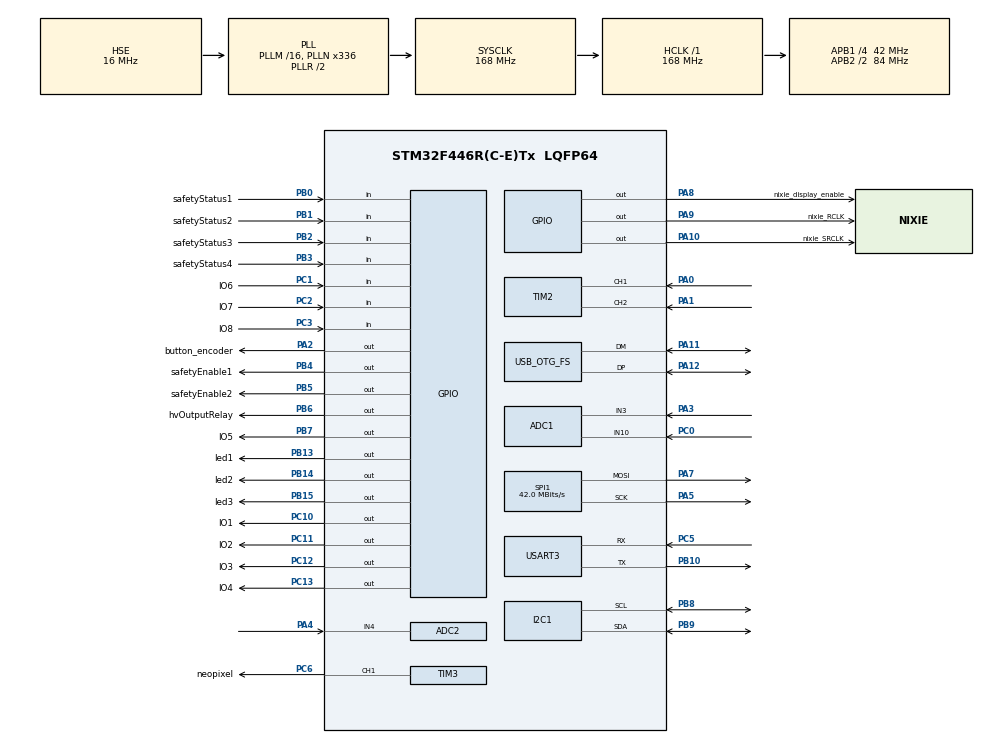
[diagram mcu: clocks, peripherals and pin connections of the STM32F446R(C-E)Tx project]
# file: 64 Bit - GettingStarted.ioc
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ADC1.Channel-0\#ChannelRegularConversion=ADC_CHANNEL_3
ADC1.NbrOfConversionFlag=1
ADC1.Rank-0\#ChannelRegularConversion=1
ADC1.SamplingTime-0\#ChannelRegularConversion=ADC_SAMPLETIME_3CYCLES
ADC1.master=1
ADC2.Channel-0\#ChannelRegularConversion=ADC_CHANNEL_4
ADC2.NbrOfConversionFlag=1
ADC2.Rank-0\#ChannelRegularConversion=1
ADC2.SamplingTime-0\#ChannelRegularConversion=ADC_SAMPLETIME_3CYCLES
Mcu.Family=STM32F4
Mcu.Name=STM32F446R(C-E)Tx
Mcu.Package=LQFP64
NVIC.PriorityGroup=NVIC_PRIORITYGROUP_4
PA0-WKUP.Signal=S_TIM2_CH1_ETR
PA1.Signal=S_TIM2_CH2
PA10.GPIO_Label=nixie_SRCLK
PA10.Signal=GPIO_Output
PA11.Mode=Device_Only
PA11.Signal=USB_OTG_FS_DM
PA12.Mode=Device_Only
PA12.Signal=USB_OTG_FS_DP
PA13.Mode=Serial_Wire
PA13.Signal=SYS_JTMS-SWDIO
PA14.Mode=Serial_Wire
PA14.Signal=SYS_JTCK-SWCLK
PA2.GPIO_Label=button_encoder
PA2.Signal=GPIO_Output
PA3.Signal=ADCx_IN3
PA4.Signal=ADCx_IN4
PA5.Mode=TX_Only_Simplex_Unidirect_Master
PA5.Signal=SPI1_SCK
PA7.Mode=TX_Only_Simplex_Unidirect_Master
PA7.Signal=SPI1_MOSI
PA8.GPIO_Label=nixie_display_enable
PA8.Signal=GPIO_Output
PA9.GPIO_Label=nixie_RCLK
PA9.Signal=GPIO_Output
PB0.GPIO_Label=safetyStatus1
PB0.Signal=GPIO_Input
PB1.GPIO_Label=safetyStatus2
PB1.Signal=GPIO_Input
PB10.Mode=Asynchronous
PB10.Signal=USART3_TX
PB13.GPIO_Label=led1
PB13.Signal=GPIO_Output
PB14.GPIO_Label=led2
PB14.Signal=GPIO_Output
PB15.GPIO_Label=led3
PB15.Signal=GPIO_Output
PB2.GPIO_Label=safetyStatus3
PB2.Signal=GPIO_Input
PB3.GPIO_Label=safetyStatus4
PB3.Signal=GPIO_Input
PB4.GPIO_Label=safetyEnable1
PB4.Signal=GPIO_Output
PB5.GPIO_Label=safetyEnable2
PB5.Signal=GPIO_Output
PB6.GPIO_Label=hvOutputRelay
PB6.Signal=GPIO_Output
PB7.GPIO_Label=IO5
PB7.Signal=GPIO_Output
PB8.Mode=I2C
PB8.Signal=I2C1_SCL
PB9.Mode=I2C
PB9.Signal=I2C1_SDA
PC0.Signal=ADCx_IN10
PC1.GPIO_Label=IO6
PC1.Signal=GPIO_Input
PC10.GPIO_Label=IO1
PC10.Signal=GPIO_Output
PC11.GPIO_Label=IO2
PC11.Signal=GPIO_Output
PC12.GPIO_Label=IO3
PC12.Signal=GPIO_Output
PC13.GPIO_Label=IO4
PC13.Signal=GPIO_Output
PC14-OSC32_IN.Mode=LSE-External-Oscillator
PC14-OSC32_IN.Signal=RCC_OSC32_IN
PC15-OSC32_OUT.Mode=LSE-External-Oscillator
PC15-OSC32_OUT.Signal=RCC_OSC32_OUT
PC2.GPIO_Label=IO7
PC2.Signal=GPIO_Input
PC3.GPIO_Label=IO8
PC3.Signal=GPIO_Input
PC5.Mode=Asynchronous
PC5.Signal=USART3_RX
PC6.GPIO_Label=neopixel
PC6.Signal=S_TIM3_CH1
PH0-OSC_IN.Mode=HSE-External-Oscillator
PH0-OSC_IN.Signal=RCC_OSC_IN
PH1-OSC_OUT.Mode=HSE-External-Oscillator
PH1-OSC_OUT.Signal=RCC_OSC_OUT
ProjectManager.HeapSize=0x200
ProjectManager.StackSize=0x400
ProjectManager.TargetToolchain=STM32CubeIDE
RCC.AHBFreq_Value=168000000
RCC.APB1CLKDivider=RCC_HCLK_DIV4
RCC.APB1Freq_Value=42000000
RCC.APB1TimFreq_Value=84000000
RCC.APB2CLKDivider=RCC_HCLK_DIV2
RCC.APB2Freq_Value=84000000
RCC.APB2TimFreq_Value=168000000
RCC.CortexFreq_Value=168000000
RCC.HCLKFreq_Value=168000000
RCC.HSE_VALUE=16000000
RCC.PLLN=336
RCC.PLLQ=7
RCC.SYSCLKFreq_VALUE=168000000
RCC.SYSCLKSource=RCC_SYSCLKSOURCE_PLLRCLK
RCC.USBFreq_Value=48000000
RCC.VCOOutputFreq_Value=336000000
SH.ADCx_IN10.0=ADC1_IN10,IN10
SH.ADCx_IN3.0=ADC1_IN3,IN3
SH.ADCx_IN4.0=ADC2_IN4,IN4
SH.S_TIM2_CH1_ETR.0=TIM2_CH1,Encoder_Interface
SH.S_TIM2_CH2.0=TIM2_CH2,Encoder_Interface
SH.S_TIM3_CH1.0=TIM3_CH1,PWM Generation1 CH1
SPI1.CalculateBaudRate=42.0 MBits/s
SPI1.Direction=SPI_DIRECTION_2LINES
SPI1.Mode=SPI_MODE_MASTER
SPI1.VirtualType=VM_MASTER
TIM3.Channel-PWM\ Generation1\ CH1=TIM_CHANNEL_1
USART3.VirtualMode=VM_ASYNC
USB_OTG_FS.VirtualMode=Device_Only
board=custom

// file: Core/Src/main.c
/* USER CODE BEGIN Header */
/**
  ******************************************************************************
  * @file           : main.c
  * @brief          : Main program body
  ******************************************************************************
  * @attention
  *
  * Copyright (c) 2025 STMicroelectronics.
  * All rights reserved.
  *
  * This software is licensed under terms that can be found in the LICENSE file
  * in the root directory of this software component.
  * If no LICENSE file comes with this software, it is provided AS-IS.
  *
  ******************************************************************************
  */
/* USER CODE END Header */
#include "main.h"

ADC_HandleTypeDef hadc1;
ADC_HandleTypeDef hadc2;

I2C_HandleTypeDef hi2c1;

SPI_HandleTypeDef hspi1;

TIM_HandleTypeDef htim2;
TIM_HandleTypeDef htim3;

UART_HandleTypeDef huart3;

PCD_HandleTypeDef hpcd_USB_OTG_FS;

void SystemClock_Config(void);
static void MX_GPIO_Init(void);
static void MX_ADC1_Init(void);
static void MX_ADC2_Init(void);
static void MX_I2C1_Init(void);
static void MX_SPI1_Init(void);
static void MX_TIM2_Init(void);
static void MX_TIM3_Init(void);
static void MX_USART3_UART_Init(void);
static void MX_USB_OTG_FS_PCD_Init(void);

int main(void)
{

  /* MCU Configuration--------------------------------------------------------*/

  /* Reset of all peripherals, Initializes the Flash interface and the Systick. */
  HAL_Init();

  /* Configure the system clock */
  SystemClock_Config();

  /* Initialize all configured peripherals */
  MX_GPIO_Init();
  MX_ADC1_Init();
  MX_ADC2_Init();
  MX_I2C1_Init();
  MX_SPI1_Init();
  MX_TIM2_Init();
  MX_TIM3_Init();
  MX_USART3_UART_Init();
  MX_USB_OTG_FS_PCD_Init();

  /* Infinite loop */
  /* USER CODE BEGIN WHILE */
  while (1)
  {

	//simple blinky
	HAL_GPIO_WritePin(GPIOB, led1_Pin, 1); //set LED HIGH
	HAL_Delay(500); //delay
	HAL_GPIO_WritePin(GPIOB, led1_Pin, 0); //set LED LOW
	HAL_Delay(500); //delay
    /* USER CODE END WHILE */

  }
}

void SystemClock_Config(void)
{
  RCC_OscInitTypeDef RCC_OscInitStruct = {0};
  RCC_ClkInitTypeDef RCC_ClkInitStruct = {0};

  /** Configure the main internal regulator output voltage
  */
  __HAL_RCC_PWR_CLK_ENABLE();
  __HAL_PWR_VOLTAGESCALING_CONFIG(PWR_REGULATOR_VOLTAGE_SCALE1);

  /** Initializes the RCC Oscillators according to the specified parameters
  * in the RCC_OscInitTypeDef structure.
  */
  RCC_OscInitStruct.OscillatorType = RCC_OSCILLATORTYPE_HSE;
  RCC_OscInitStruct.HSEState = RCC_HSE_ON;
  RCC_OscInitStruct.PLL.PLLState = RCC_PLL_ON;
  RCC_OscInitStruct.PLL.PLLSource = RCC_PLLSOURCE_HSE;
  RCC_OscInitStruct.PLL.PLLM = 16;
  RCC_OscInitStruct.PLL.PLLN = 336;
  RCC_OscInitStruct.PLL.PLLP = RCC_PLLP_DIV2;
  RCC_OscInitStruct.PLL.PLLQ = 7;
  RCC_OscInitStruct.PLL.PLLR = 2;
  if (HAL_RCC_OscConfig(&RCC_OscInitStruct) != HAL_OK)
  {
    Error_Handler();
  }

  /** Initializes the CPU, AHB and APB buses clocks
  */
  RCC_ClkInitStruct.ClockType = RCC_CLOCKTYPE_HCLK|RCC_CLOCKTYPE_SYSCLK
                              |RCC_CLOCKTYPE_PCLK1|RCC_CLOCKTYPE_PCLK2;
  RCC_ClkInitStruct.SYSCLKSource = RCC_SYSCLKSOURCE_PLLRCLK;
  RCC_ClkInitStruct.AHBCLKDivider = RCC_SYSCLK_DIV1;
  RCC_ClkInitStruct.APB1CLKDivider = RCC_HCLK_DIV4;
  RCC_ClkInitStruct.APB2CLKDivider = RCC_HCLK_DIV2;

  if (HAL_RCC_ClockConfig(&RCC_ClkInitStruct, FLASH_LATENCY_5) != HAL_OK)
  {
    Error_Handler();
  }
}

static void MX_ADC1_Init(void)
{

  ADC_ChannelConfTypeDef sConfig = {0};

  /** Configure the global features of the ADC (Clock, Resolution, Data Alignment and number of conversion)
  */
  hadc1.Instance = ADC1;
  hadc1.Init.ClockPrescaler = ADC_CLOCK_SYNC_PCLK_DIV4;
  hadc1.Init.Resolution = ADC_RESOLUTION_12B;
  hadc1.Init.ScanConvMode = DISABLE;
  hadc1.Init.ContinuousConvMode = DISABLE;
  hadc1.Init.DiscontinuousConvMode = DISABLE;
  hadc1.Init.ExternalTrigConvEdge = ADC_EXTERNALTRIGCONVEDGE_NONE;
  hadc1.Init.ExternalTrigConv = ADC_SOFTWARE_START;
  hadc1.Init.DataAlign = ADC_DATAALIGN_RIGHT;
  hadc1.Init.NbrOfConversion = 1;
  hadc1.Init.DMAContinuousRequests = DISABLE;
  hadc1.Init.EOCSelection = ADC_EOC_SINGLE_CONV;
  if (HAL_ADC_Init(&hadc1) != HAL_OK)
  {
    Error_Handler();
  }

  /** Configure for the selected ADC regular channel its corresponding rank in the sequencer and its sample time.
  */
  sConfig.Channel = ADC_CHANNEL_3;
  sConfig.Rank = 1;
  sConfig.SamplingTime = ADC_SAMPLETIME_3CYCLES;
  if (HAL_ADC_ConfigChannel(&hadc1, &sConfig) != HAL_OK)
  {
    Error_Handler();
  }

}

static void MX_ADC2_Init(void)
{

  ADC_ChannelConfTypeDef sConfig = {0};

  /** Configure the global features of the ADC (Clock, Resolution, Data Alignment and number of conversion)
  */
  hadc2.Instance = ADC2;
  hadc2.Init.ClockPrescaler = ADC_CLOCK_SYNC_PCLK_DIV4;
  hadc2.Init.Resolution = ADC_RESOLUTION_12B;
  hadc2.Init.ScanConvMode = DISABLE;
  hadc2.Init.ContinuousConvMode = DISABLE;
  hadc2.Init.DiscontinuousConvMode = DISABLE;
  hadc2.Init.ExternalTrigConvEdge = ADC_EXTERNALTRIGCONVEDGE_NONE;
  hadc2.Init.ExternalTrigConv = ADC_SOFTWARE_START;
  hadc2.Init.DataAlign = ADC_DATAALIGN_RIGHT;
  hadc2.Init.NbrOfConversion = 1;
  hadc2.Init.DMAContinuousRequests = DISABLE;
  hadc2.Init.EOCSelection = ADC_EOC_SINGLE_CONV;
  if (HAL_ADC_Init(&hadc2) != HAL_OK)
  {
    Error_Handler();
  }

  /** Configure for the selected ADC regular channel its corresponding rank in the sequencer and its sample time.
  */
  sConfig.Channel = ADC_CHANNEL_4;
  sConfig.Rank = 1;
  sConfig.SamplingTime = ADC_SAMPLETIME_3CYCLES;
  if (HAL_ADC_ConfigChannel(&hadc2, &sConfig) != HAL_OK)
  {
    Error_Handler();
  }

}

static void MX_I2C1_Init(void)
{

  hi2c1.Instance = I2C1;
  hi2c1.Init.ClockSpeed = 100000;
  hi2c1.Init.DutyCycle = I2C_DUTYCYCLE_2;
  hi2c1.Init.OwnAddress1 = 0;
  hi2c1.Init.AddressingMode = I2C_ADDRESSINGMODE_7BIT;
  hi2c1.Init.DualAddressMode = I2C_DUALADDRESS_DISABLE;
  hi2c1.Init.OwnAddress2 = 0;
  hi2c1.Init.GeneralCallMode = I2C_GENERALCALL_DISABLE;
  hi2c1.Init.NoStretchMode = I2C_NOSTRETCH_DISABLE;
  if (HAL_I2C_Init(&hi2c1) != HAL_OK)
  {
    Error_Handler();
  }

}

static void MX_SPI1_Init(void)
{

  /* SPI1 parameter configuration*/
  hspi1.Instance = SPI1;
  hspi1.Init.Mode = SPI_MODE_MASTER;
  hspi1.Init.Direction = SPI_DIRECTION_2LINES;
  hspi1.Init.DataSize = SPI_DATASIZE_8BIT;
  hspi1.Init.CLKPolarity = SPI_POLARITY_LOW;
  hspi1.Init.CLKPhase = SPI_PHASE_1EDGE;
  hspi1.Init.NSS = SPI_NSS_SOFT;
  hspi1.Init.BaudRatePrescaler = SPI_BAUDRATEPRESCALER_2;
  hspi1.Init.FirstBit = SPI_FIRSTBIT_MSB;
  hspi1.Init.TIMode = SPI_TIMODE_DISABLE;
  hspi1.Init.CRCCalculation = SPI_CRCCALCULATION_DISABLE;
  hspi1.Init.CRCPolynomial = 10;
  if (HAL_SPI_Init(&hspi1) != HAL_OK)
  {
    Error_Handler();
  }

}

static void MX_TIM2_Init(void)
{

  TIM_Encoder_InitTypeDef sConfig = {0};
  TIM_MasterConfigTypeDef sMasterConfig = {0};

  htim2.Instance = TIM2;
  htim2.Init.Prescaler = 0;
  htim2.Init.CounterMode = TIM_COUNTERMODE_UP;
  htim2.Init.Period = 4294967295;
  htim2.Init.ClockDivision = TIM_CLOCKDIVISION_DIV1;
  htim2.Init.AutoReloadPreload = TIM_AUTORELOAD_PRELOAD_DISABLE;
  sConfig.EncoderMode = TIM_ENCODERMODE_TI1;
  sConfig.IC1Polarity = TIM_ICPOLARITY_RISING;
  sConfig.IC1Selection = TIM_ICSELECTION_DIRECTTI;
  sConfig.IC1Prescaler = TIM_ICPSC_DIV1;
  sConfig.IC1Filter = 0;
  sConfig.IC2Polarity = TIM_ICPOLARITY_RISING;
  sConfig.IC2Selection = TIM_ICSELECTION_DIRECTTI;
  sConfig.IC2Prescaler = TIM_ICPSC_DIV1;
  sConfig.IC2Filter = 0;
  if (HAL_TIM_Encoder_Init(&htim2, &sConfig) != HAL_OK)
  {
    Error_Handler();
  }
  sMasterConfig.MasterOutputTrigger = TIM_TRGO_RESET;
  sMasterConfig.MasterSlaveMode = TIM_MASTERSLAVEMODE_DISABLE;
  if (HAL_TIMEx_MasterConfigSynchronization(&htim2, &sMasterConfig) != HAL_OK)
  {
    Error_Handler();
  }

}

static void MX_TIM3_Init(void)
{

  TIM_MasterConfigTypeDef sMasterConfig = {0};
  TIM_OC_InitTypeDef sConfigOC = {0};

  htim3.Instance = TIM3;
  htim3.Init.Prescaler = 0;
  htim3.Init.CounterMode = TIM_COUNTERMODE_UP;
  htim3.Init.Period = 65535;
  htim3.Init.ClockDivision = TIM_CLOCKDIVISION_DIV1;
  htim3.Init.AutoReloadPreload = TIM_AUTORELOAD_PRELOAD_DISABLE;
  if (HAL_TIM_PWM_Init(&htim3) != HAL_OK)
  {
    Error_Handler();
  }
  sMasterConfig.MasterOutputTrigger = TIM_TRGO_RESET;
  sMasterConfig.MasterSlaveMode = TIM_MASTERSLAVEMODE_DISABLE;
  if (HAL_TIMEx_MasterConfigSynchronization(&htim3, &sMasterConfig) != HAL_OK)
  {
    Error_Handler();
  }
  sConfigOC.OCMode = TIM_OCMODE_PWM1;
  sConfigOC.Pulse = 0;
  sConfigOC.OCPolarity = TIM_OCPOLARITY_HIGH;
  sConfigOC.OCFastMode = TIM_OCFAST_DISABLE;
  if (HAL_TIM_PWM_ConfigChannel(&htim3, &sConfigOC, TIM_CHANNEL_1) != HAL_OK)
  {
    Error_Handler();
  }
  HAL_TIM_MspPostInit(&htim3);

}

static void MX_USART3_UART_Init(void)
{

  huart3.Instance = USART3;
  huart3.Init.BaudRate = 115200;
  huart3.Init.WordLength = UART_WORDLENGTH_8B;
  huart3.Init.StopBits = UART_STOPBITS_1;
  huart3.Init.Parity = UART_PARITY_NONE;
  huart3.Init.Mode = UART_MODE_TX_RX;
  huart3.Init.HwFlowCtl = UART_HWCONTROL_NONE;
  huart3.Init.OverSampling = UART_OVERSAMPLING_16;
  if (HAL_UART_Init(&huart3) != HAL_OK)
  {
    Error_Handler();
  }

}

static void MX_USB_OTG_FS_PCD_Init(void)
{

  hpcd_USB_OTG_FS.Instance = USB_OTG_FS;
  hpcd_USB_OTG_FS.Init.dev_endpoints = 6;
  hpcd_USB_OTG_FS.Init.speed = PCD_SPEED_FULL;
  hpcd_USB_OTG_FS.Init.dma_enable = DISABLE;
  hpcd_USB_OTG_FS.Init.phy_itface = PCD_PHY_EMBEDDED;
  hpcd_USB_OTG_FS.Init.Sof_enable = DISABLE;
  hpcd_USB_OTG_FS.Init.low_power_enable = DISABLE;
  hpcd_USB_OTG_FS.Init.lpm_enable = DISABLE;
  hpcd_USB_OTG_FS.Init.vbus_sensing_enable = DISABLE;
  hpcd_USB_OTG_FS.Init.use_dedicated_ep1 = DISABLE;
  if (HAL_PCD_Init(&hpcd_USB_OTG_FS) != HAL_OK)
  {
    Error_Handler();
  }

}

static void MX_GPIO_Init(void)
{
  GPIO_InitTypeDef GPIO_InitStruct = {0};

  /* GPIO Ports Clock Enable */
  __HAL_RCC_GPIOC_CLK_ENABLE();
  __HAL_RCC_GPIOH_CLK_ENABLE();
  __HAL_RCC_GPIOA_CLK_ENABLE();
  __HAL_RCC_GPIOB_CLK_ENABLE();

  /*Configure GPIO pin Output Level */
  HAL_GPIO_WritePin(GPIOC, IO4_Pin|IO1_Pin|IO2_Pin|IO3_Pin, GPIO_PIN_RESET);

  /*Configure GPIO pin Output Level */
  HAL_GPIO_WritePin(GPIOA, button_encoder_Pin|nixie_display_enable_Pin|nixie_RCLK_Pin|nixie_SRCLK_Pin, GPIO_PIN_RESET);

  /*Configure GPIO pin Output Level */
  HAL_GPIO_WritePin(GPIOB, led1_Pin|led2_Pin|led3_Pin|safetyEnable1_Pin
                          |safetyEnable2_Pin|hvOutputRelay_Pin|IO5_Pin, GPIO_PIN_RESET);

  /*Configure GPIO pins : IO4_Pin IO1_Pin IO2_Pin IO3_Pin */
  GPIO_InitStruct.Pin = IO4_Pin|IO1_Pin|IO2_Pin|IO3_Pin;
  GPIO_InitStruct.Mode = GPIO_MODE_OUTPUT_PP;
  GPIO_InitStruct.Pull = GPIO_NOPULL;
  GPIO_InitStruct.Speed = GPIO_SPEED_FREQ_LOW;
  HAL_GPIO_Init(GPIOC, &GPIO_InitStruct);

  /*Configure GPIO pins : IO6_Pin IO7_Pin IO8_Pin */
  GPIO_InitStruct.Pin = IO6_Pin|IO7_Pin|IO8_Pin;
  GPIO_InitStruct.Mode = GPIO_MODE_INPUT;
  GPIO_InitStruct.Pull = GPIO_NOPULL;
  HAL_GPIO_Init(GPIOC, &GPIO_InitStruct);

  /*Configure GPIO pins : button_encoder_Pin nixie_display_enable_Pin nixie_RCLK_Pin nixie_SRCLK_Pin */
  GPIO_InitStruct.Pin = button_encoder_Pin|nixie_display_enable_Pin|nixie_RCLK_Pin|nixie_SRCLK_Pin;
  GPIO_InitStruct.Mode = GPIO_MODE_OUTPUT_PP;
  GPIO_InitStruct.Pull = GPIO_NOPULL;
  GPIO_InitStruct.Speed = GPIO_SPEED_FREQ_LOW;
  HAL_GPIO_Init(GPIOA, &GPIO_InitStruct);

  /*Configure GPIO pins : safetyStatus1_Pin safetyStatus2_Pin safetyStatus3_Pin safetyStatus4_Pin */
  GPIO_InitStruct.Pin = safetyStatus1_Pin|safetyStatus2_Pin|safetyStatus3_Pin|safetyStatus4_Pin;
  GPIO_InitStruct.Mode = GPIO_MODE_INPUT;
  GPIO_InitStruct.Pull = GPIO_NOPULL;
  HAL_GPIO_Init(GPIOB, &GPIO_InitStruct);

  /*Configure GPIO pins : led1_Pin led2_Pin led3_Pin safetyEnable1_Pin
                           safetyEnable2_Pin hvOutputRelay_Pin IO5_Pin */
  GPIO_InitStruct.Pin = led1_Pin|led2_Pin|led3_Pin|safetyEnable1_Pin
                          |safetyEnable2_Pin|hvOutputRelay_Pin|IO5_Pin;
  GPIO_InitStruct.Mode = GPIO_MODE_OUTPUT_PP;
  GPIO_InitStruct.Pull = GPIO_NOPULL;
  GPIO_InitStruct.Speed = GPIO_SPEED_FREQ_LOW;
  HAL_GPIO_Init(GPIOB, &GPIO_InitStruct);

}

void Error_Handler(void)
{
  __disable_irq();
  while (1)
  {
  }
}
